# BE-U1000 register map
Vendor: BAIKAL ELECTRONICS, JSC; File version: 1.0
CPU: RISC-V r0p0, little endian, no MPU, no FPU, 3 interrupt priority bits
Registers are 32-bit, read-write, reset 0x0 unless marked. A register's access mark holds for its fields unless they carry their own. Offsets are from the block's base; [hi:lo] are bit positions; {n}, {i} and the like mark numbered series; 'fields as' and 'values as' point back to an identical list; <NAME> marks a mode.

## PWMA0 — Advanced-control Timer
Base 0x14004000
Same registers: PWMA1 0x14005000, PWMA2 0x14006000, PWMA3 0x14007000
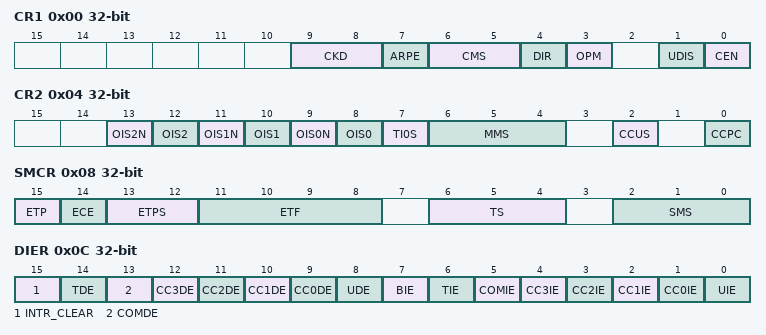
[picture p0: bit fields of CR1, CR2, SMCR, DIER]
0x00 CR1 — Control register 1
  [9:8] CKD — Clock division
    0=DIV1 (Clock is not divided); 1=DIV2 (Clock is divided by 2); 2=DIV4 (Clock is divided by 4)
  [7] ARPE — Auto-reload preload enable
    0=DISABLE; 1=ENABLE
  [6:5] CMS — Center-aligned mode selection
    0=EDGE_ALIGNED (Edge-aligned mode); 1=CENTER_ALIGNED_1 (Center-aligned mode 1); 2=CENTER_ALIGNED_2 (Center-aligned mode 2); 3=CENTER_ALIGNED_3 (Center-aligned mode 3)
  [4] DIR — Direction
    0=UP (Count up); 1=DOWN (Count down)
  [3] OPM — One pulse mode
    0=REPETITIVE (Counter is not stopped at update event); 1=SINGLE (Counter stops counting at the next update event)
  [1] UDIS — Update disable
    0=DISABLE; 1=ENABLE
  [0] CEN — Counter enable
    0=DISABLE; 1=ENABLE
0x04 CR2 — Control register 2
  [13] OIS2N — Output Idle state 2 (OC2N output)
    0=IDLE_LOW (OC2N=1 after a dead-time when MOE=0); 1=IDLE_HIGH (OC2N=1 after a dead-time when MOE=0)
  [12] OIS2 — Output Idle state 2 (OC2 output)
    0=IDLE_LOW (OC2=0 (after a dead-time if OC is implemented) when MOE=0); 1=IDLE_HIGH (OC2=1 (after a dead-time if OC is implemented) when MOE=0)
  [11] OIS1N — Output Idle state 1 (OC1N output)
    0=IDLE_LOW (OC1N=0 after a dead-time when MOE=0); 1=IDLE_HIGH (OC1N=1 after a dead-time when MOE=0)
  [10] OIS1 — Output Idle state 1 (OC1 output)
    0=IDLE_LOW (OC1=0 (after a dead-time if OC is implemented) when MOE=0); 1=IDLE_HIGH (OC1=1 (after a dead-time if OC is implemented) when MOE=0)
  [9] OIS0N — Output Idle state 0 (OC0N output)
    0=IDLE_LOW (OC0N=0 after a dead-time when MOE=0); 1=IDLE_HIGH (OC0N=1 after a dead-time when MOE=0)
  [8] OIS0 — Output Idle state 0 (OC0 output)
    0=IDLE_LOW (OC0=0 (after a dead-time if OC is implemented) when MOE=0); 1=IDLE_HIGH (OC0=1 (after a dead-time if OC is implemented) when MOE=0)
  [7] TI0S — TI0 selection
    0=DISABLE; 1=ENABLE
  [6:4] MMS — Master mode selection
    0=RESET (Reset; TRGO=EGR_UG); 1=ENABLE (Enable; TRGO=CEN or TRGI); 2=UPDATE (Update; TRGO=EUV); 3=CC0IF (Compare Pulse; TRGO=CC0IF); {v}=OC{v-4}REF (Compare; TRGO=OC{v-4}REF) (v=4..7)
  [2] CCUS — Capture/compare control update selection
    0=COMG_ONLY (If buffering of capture/compare control bits \ (CCxE, CCxNE, OCxM) is used; \ Update occurs when CR2_CCPC=1 and COMG=1); 1=COMG_TRGI (If buffering of capture/compare control bits \ (CCxE, CCxNE, OCxM) is used; \ The update occurs when CR2_CCPC=1 and (COMG=1 or posedge(TRGI)))
  [0] CCPC — Capture/Compare preloaded control
    0=DISABLE (CCxE, CCxNE and OCxM bits are not preloaded); 1=ENABLE (CCxE, CCxNE and OCxM bits are preloaded)
0x08 SMCR — Slave mode control register
  [15] ETP — External trigger polarity
    0=NONINVERTED (ETR is non-inverted, active at high level or rising edge); 1=INVERTED (ETR is inverted, active at low level or falling edge)
  [14] ECE — External clock enable
    0=DISABLE; 1=ENABLE
  [13:12] ETPS — External trigger prescaler
    0=DIV1 (ETR signal is not divided); 1=DIV2 (ETR signal is divided by 2); 2=DIV4 (ETR signal is divided by 4); 3=DIV8 (ETR signal is divided by 8)
  [11:8] ETF — External trigger filter
    0=FDIV1 (f_sampling=f_dts; Filter not used); 1=FDIV1_N2 (f_sampling=f_ck_int, N=2); 2=FDIV1_N4 (f_sampling=f_ck_int, N=4); 3=FDIV1_N8 (f_sampling=f_ck_int, N=8); 4=FDIV2_N6 (f_sampling=f_dts/2, N=6); 5=FDIV2_N8 (f_sampling=f_dts/2, N=8); 6=FDIV4_N6 (f_sampling=f_dts/4, N=6); 7=FDIV4_N8 (f_sampling=f_dts/4, N=8); 8=FDIV8_N6 (f_sampling=f_dts/8, N=6); 9=FDIV8_N8 (f_sampling=f_dts/8, N=8); 10=FDIV16_N5 (f_sampling=f_dts/16, N=5); 11=FDIV16_N6 (f_sampling=f_dts/16, N=6); 12=FDIV16_N8 (f_sampling=f_dts/16, N=8); 13=FDIV32_N5 (f_sampling=f_dts/32, N=5); 14=FDIV32_N6 (f_sampling=f_dts/32, N=6); 15=FDIV32_N8 (f_sampling=f_dts/32, N=8)
  [6:4] TS — Trigger selection
    0=ITR0 (Internal Trigger 0 (ITR0)); 1=ITR1 (Internal Trigger 1 (ITR1)); 2=ITR2 (Internal Trigger 2 (ITR2)); 4=TI0F_ED (TI0 Edge Detector (TI0F_ED)); 5=TI0FP0 (Filtered Timer Input 0 (TI0FP0)); 6=TI1FP1 (Filtered Timer Input 1 (TI1FP1)); 7=ETRF (External Trigger Input (ETRF))
  [2:0] SMS — Slave mode selection
    0=DISABLE (Slave mode disabled; At prescaler input: CEN=1 and "internal clock signal"); 4=RESET (Reset mode; posedge(TRGI) resets the counter and updates the registers); 5=GATED (Gated mode; The counter is started by posedge (TRGI); \ The counter is stopped by negedge(TRGI); The counter is not reset.); 6=TRIGGER (Trigger mode; The counter is started by posedge(TRGI); Stopping the counter \ is not controlled. The counter is not reset.); 7=EXTCLK_1 (External Clock Mode 1; The counter is clocked by posedge(TRGI).)
0x0C DIER — DMA/Interrupt enable register
  [all] fields
    0=DISABLE; 1=ENABLE
  [15] INTR_CLEAR — Interrupt clear
  [14] TDE — Trigger DMA request enable
  [13] COMDE — COM DMA request enable
  [n+9] CC{n}DE (n=0..3) — Capture/Compare {n} DMA request enable
  [8] UDE — Update DMA request enable
  [7] BIE — Break interrupt enable
  [6] TIE — Trigger interrupt enable
  [5] COMIE — COM interrupt enable
  [n+1] CC{n}IE (n=0..3) — Capture/Compare {n} interrupt enable
  [0] UIE — Update interrupt enable
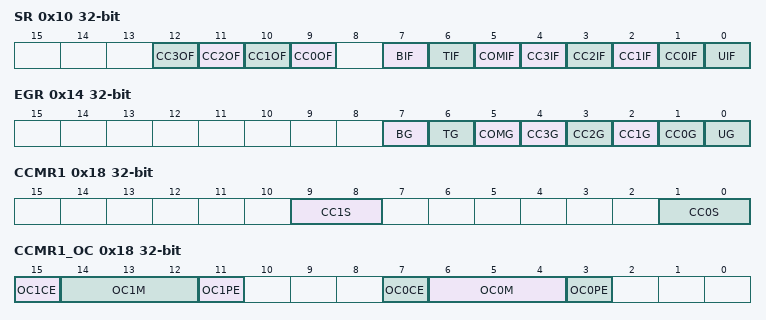
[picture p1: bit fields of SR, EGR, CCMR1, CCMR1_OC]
0x10 SR — Status register
  [all] fields
    0=DISABLE; 1=ENABLE
  [n+9] CC{n}OF (n=0..3) — Capture/Compare {n} overcapture flag
  [7] BIF — Break interrupt flag
  [6] TIF — Trigger interrupt flag
  [5] COMIF — COM interrupt flag
  [n+1] CC{n}IF (n=0..3) — Capture/Compare {n} interrupt flag
  [0] UIF — Update interrupt flag
0x14 EGR — Event generation register
  [all] fields
    0=DISABLE; 1=ENABLE
  [7] BG — Break generation
  [6] TG — Trigger generation
  [5] COMG — Capture/Compare control update generation
  [n+1] CC{n}G (n=0..3) — Capture/Compare {n} generation
  [0] UG — Update generation
0x18 CCMR1 — Capture/Compare mode register 1
  [9:8] CC1S — Capture/Compare 1 selection
    0=OC (Channel 1 configured as output); 1=IC_TI1 (Channel 1 configured as input; IC1 signal connected to TI1); 2=IC_TI0 (Channel 1 configured as input; IC1 signal connected to TI0); 3=IC_TRC (Channel 1 configured as input; IC1 signal connected to TRC when SMCR_TS=1)
  [1:0] CC0S — Capture/Compare 0 selection
    0=OC (Channel 0 configured as output); 1=IC_TI0 (Channel 0 configured as input; IC0 signal connected to TI0); 2=IC_TI1 (Channel 0 configured as input; IC0 signal connected to TI1); 3=IC_TRC (Channel 0 configured as input; IC0 signal connected to TRC when SMCR_TS=1)
0x18 CCMR1_OC — Capture/Compare mode register 1, Output Compare
  [15] OC1CE — Output Compare 1 clear enable
    0=DISABLE; 1=ENABLE
  [14:12] OC1M — Output Compare 1 mode
    0=FROZEN (Frozen; When CNT=CCR1 the output states do not change.); 1=ACTIVE (Set the Channel 1 output to the active level when the comparison circuit \ is triggered; When CNT=CCR1, OC1REF=1 is set.); 2=INACTIVE (Set the Channel 1 output to the inactive level when the comparison circuit \ is triggered; When CNT=CCR1, OC1REF=0 is set.); 3=TOGGLE (Toggle; When CNT=CCR1, OC1REF = not OC1REF is set.); 4=FORCED_INACTIVE (Force switch to the inactive state; OC1REF=0.); 5=FORCED_ACTIVE (Force switch to the active state; OC1REF=1.); 6=PWM1 (PWM mode 1; When counting up, Channel 1 is active (OC1REF=1) \ until (CNT less-than-or-equal CCR1), otherwise Channel 1 is inactive (OC1REF=0); \ When counting down, Channel 1 is inactive (OC1REF=0) \ until (CNT greater-than-or-equal CCR1), otherwise Channel 1 is active (OC1REF=1).); 7=PWM2 (PWM Mode 2; When counting up, Channel 1 is inactive (OC1REF=0) \ until (CNT less-than-or-equal CCR1), otherwise Channel 1 is active (OC1REF=1); \ When counting down, Channel 1 is active (OC1REF=1) \ until (CNT greater-than-or-equal CCR1), otherwise Channel 1 is inactive (OC1REF=1).)
  [11] OC1PE — Output Compare 1 preload enable
    0=DISABLE; 1=ENABLE
  [7] OC0CE — Output Compare 0 clear enable
    0=DISABLE; 1=ENABLE
  [6:4] OC0M — Output Compare 0 mode
    0=FROZEN (Frozen; When CNT=CCR0, the output states do not change.); 1=ACTIVE (Set the Channel 0 output to the active level when the comparison circuit is triggered; When CNT=CCR0, OC0REF=1 is set.); 2=INACTIVE (Set the Channel 0 output to the inactive level when the comparison circuit is triggered; When CNT=CCR0, OC0REF=0 is set.); 3=TOGGLE (Toggle; When CNT=CCR0, OC0REF = not OC0REF is set.); 4=FORCED_INACTIVE (Force switch to the inactive state; OC0REF=0.); 5=FORCED_ACTIVE (Force switch to the active state; OC0REF=1.); 6=PWM1 (PWM mode 1; When counting up, Channel 0 is active (OC0REF=1) \ until (CNT less-than-or-equal CCR0), otherwise Channel 0 is inactive (OC0REF=0); \ When counting down, Channel 0 is inactive (OC0REF=0) \ until (CNT greater-than-or-equal CCR0), otherwise Channel 0 is active (OC0REF=1).); 7=PWM2 (PWM Mode 2; When counting up, Channel 0 is inactive (OC0REF=0) \ until (CNT less-than-or-equal CCR0), otherwise Channel 0 is active (OC0REF=1); \ When counting down, Channel 0 is active (OC0REF=1) \ until (CNT greater-than-or-equal CCR0), otherwise Channel 0 is inactive (OC0REF=1).)
  [3] OC0PE — Output Compare 0 preload enable
    0=DISABLE; 1=ENABLE
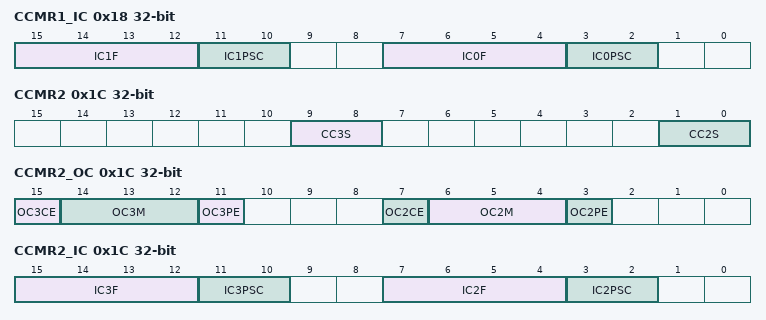
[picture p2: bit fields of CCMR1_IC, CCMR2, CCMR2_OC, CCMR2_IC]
0x18 CCMR1_IC — Capture/Compare mode register 1, Input Capture
  [15:12] IC1F — Input capture 1 filter
    values as SMCR.ETF
  [11:10] IC1PSC — Input capture 1 prescaler
    0=DIV1 (Prescaler is not used); 1=DIV2 (Prescaler is 2); 2=DIV4 (Prescaler is 4); 3=DIV8 (Prescaler is 8)
  [7:4] IC0F — Input capture 0 filter
    values as SMCR.ETF
  [3:2] IC0PSC — Input capture 0 prescaler
    values as IC1PSC
0x1C CCMR2 — Capture/Compare mode register 2
  [9:8] CC3S — Capture/Compare 3 selection
    0=OC (Channel 3 configured as output); 1=IC_TI3 (Channel 3 configured as input; IC3 signal connected to TI3); 2=IC_TI2 (Channel 3 configured as input; IC3 signal connected to TI2); 3=IC (Channel 3 configured as input; IC3 signal connected to TRC when SMCR_TS=1)
  [1:0] CC2S — Capture/Compare 2 selection
    0=OC (Channel 2 configured as output); 1=IC_TI2 (Channel 2 configured as input; IC2 signal connected to TI2); 2=IC_TI3 (Channel 2 configured as input; IC2 signal connected to TI3); 3=IC_TRC (Channel 2 configured as input; IC2 signal connected to TRC when SMCR_TS=1)
0x1C CCMR2_OC — Capture/Compare mode register 2, Output Compare
  [15] OC3CE — Output Compare 3 clear enable
    0=DISABLE; 1=ENABLE
  [14:12] OC3M — Output Compare 3 mode
    0=FROZEN (Frozen; When CNT=CCR3 the output states do not change.); 1=ACTIVE (Set the Channel 3 output to the active level when the comparison circuit \ is triggered; When CNT=CCR3, OC3REF=1 is set.); 2=INACTIVE (Set the Channel 3 output to the inactive level when the comparison circuit \ is triggered; When CNT=CCR3, OC3REF=0 is set.); 3=TOGGLE (Toggle; When CNT=CCR3, OC3REF = not OC3REF is set.); 4=FORCED_INACTIVE (Force switch to the inactive state; OC3REF=0.); 5=FORCED_ACTIVE (Force switch to the active state; OC3REF=1.); 6=PWM1 (PWM mode 1; When counting up, Channel 3 is active (OC3REF=1) \ until (CNT less-than-or-equal CCR3), otherwise Channel 3 is inactive (OC3REF=0); \ When counting down, Channel 3 is inactive (OC3REF=0) \ until (CNT greater-than-or-equal CCR3), otherwise Channel 3 is active (OC3REF=1).); 7=PWM2 (PWM Mode 2; When counting up, Channel 3 is inactive (OC3REF=0) \ until (CNT less-than-or-equal CCR3), otherwise Channel 3 is active (OC3REF=1); \ When counting down, Channel 3 is active (OC3REF=1) \ until (CNT greater-than-or-equal CCR3), otherwise Channel 3 is inactive (OC3REF=1).)
  [11] OC3PE — Output Compare 3 preload enable
    0=DISABLE; 1=ENABLE
  [7] OC2CE — Output Compare 2 clear enable
    0=DISABLE; 1=ENABLE
  [6:4] OC2M — Output Compare 2 mode
    0=FROZEN (Frozen; When CNT=CCR2 the output states do not change.); 1=ACTIVE (Set the Channel 2 output to the active level when the comparison circuit \ is triggered; When CNT=CCR2, OC2REF=1 is set.); 2=INACTIVE (Set the Channel 2 output to the inactive level when the comparison circuit \ is triggered; When CNT=CCR2, OC2REF=0 is set.); 3=TOGGLE (Toggle; When CNT=CCR2, OC2REF = not OC2REF is set.); 4=FORCED_INACTIVE (Force switch to the inactive state; OC2REF=0.); 5=FORCED_ACTIVE (Force switch to the active state; OC2REF=1.); 6=PWM1 (PWM mode 1; When counting up, Channel 2 is active (OC2REF=1) \ until (CNT less-than-or-equal CCR2), otherwise Channel 2 is inactive (OC2REF=0); \ When counting down, Channel 2 is inactive (OC2REF=0) \ until (CNT greater-than-or-equal CCR2), otherwise Channel 2 is active (OC2REF=1).); 7=PWM2 (PWM Mode 2; When counting up, Channel 2 is inactive (OC2REF=0) \ until (CNT less-than-or-equal CCR2), otherwise Channel 2 is active (OC2REF=1); \ When counting down, Channel 2 is active (OC2REF=1) \ until (CNT greater-than-or-equal CCR2), otherwise Channel 2 is inactive (OC2REF=1).)
  [3] OC2PE — Output Compare 2 preload enable
    0=DISABLE; 1=ENABLE
0x1C CCMR2_IC — Capture/Compare mode register 2, Input Capture
  [15:12] IC3F — Input capture 3 filter
    values as SMCR.ETF
  [11:10] IC3PSC — Input capture 3 prescaler
    values as CCMR1_IC.IC1PSC
  [7:4] IC2F — Input capture 2 filter
    values as SMCR.ETF
  [3:2] IC2PSC — Input capture 2 prescaler
    values as CCMR1_IC.IC1PSC
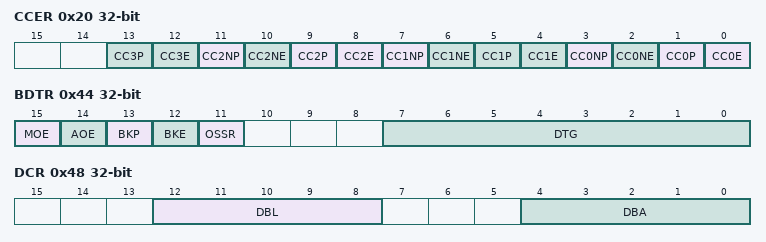
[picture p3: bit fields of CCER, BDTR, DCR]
0x20 CCER — Capture/Compare enable register
  [4n+1] CC{n}P (n=0..3) — Capture/Compare {n} output polarity
    0=HIGH (Channel {n} configured as output: active high); 1=LOW (Channel {n} configured as output: active low); 0=NONINVERTED (Channel {n} configured as input: non-inverted/rising edge); 1=INVERTED (Channel {n} configured as input: inverted/falling edge)
  [4n] CC{n}E (n=0..3) — Capture/Compare {n} output enable
    0=DISABLE (OC{n} is not active); 1=ENABLE (OC{n} signal is output on the corresponding output pin)
  [11] CC2NP — Capture/Compare 2 complementary output polarity
    0=HIGH (Channel 2 configured as output: active high); 1=LOW (Channel 2 configured as output: active low); 0=NONINVERTED (This bit is used in conjunction with CC2P to define the polarity of TI0FP1 and TI1FP1. Refer to CC2P description. Channel 2 configured as input: non-inverted/rising edge); 1=INVERTED (Channel 2 configured as input: inverted/falling edge)
  [10] CC2NE — Capture/Compare 2 complementary output enable
    0=DISABLE (OC2N is not active); 1=ENABLE (OC2N signal is output on the corresponding output pin)
  [7] CC1NP — Capture/Compare 1 complementary output polarity
    0=HIGH (Channel 1 configured as output: active high); 1=LOW (Channel 1 configured as output: active low); 0=NONINVERTED (This bit is used in conjunction with CC1P to define the polarity of TI0FP1 and TI1FP1. Refer to CC1P description. Channel 1 configured as input: non-inverted/rising edge); 1=INVERTED (Channel 1 configured as input: inverted/falling edge)
  [6] CC1NE — Capture/Compare 1 complementary output enable
    0=DISABLE (OC1N is not active); 1=ENABLE (OC1N signal is output on the corresponding output pin)
  [3] CC0NP — Capture/Compare 0 complementary output polarity
    0=HIGH (Channel 0 configured as output: active high); 1=LOW (Channel 0 configured as output: active low); 0=NONINVERTED (This bit is used in conjunction with CC0P to define the polarity of TI0FP1 and TI1FP1. Refer to CC0P description. Channel 0 configured as input: non-inverted/rising edge); 1=INVERTED (Channel 0 configured as input: inverted/falling edge)
  [2] CC0NE — Capture/Compare 0 complementary output enable
    0=DISABLE (OC0N is not active); 1=ENABLE (OC0N signal is output on the corresponding output pin)
0x24 CNT — Counter register
  [15:0] CNT — Counter
0x28 PSC — Prescaler register
  [15:0] PSC — Prescaler
0x2C ARR — Auto-reload register
  [15:0] ARR
0x30 RCR — Repetition counter register
  [7:0] RCR
{0x34+4i} CCR{i} (i=0..3) — Capture/Compare register {i}
  [15:0] CCR{i}
0x44 BDTR — Break and dead-time register
  [15] MOE — Main output enable
    0=DISABLE; 1=ENABLE
  [14] AOE — Automatic output enable
    0=DISABLE (MOE can be set only by software); 1=ENABLE (MOE can be set by software or automatically at the next update event)
  [13] BKP — Break polarity
    0=LOW (Break input BRK is active low); 1=HIGH (Break input BRK is active high)
  [12] BKE — Break enable
    0=DISABLE (Break function disabled); 1=ENABLE (Break function enabled)
  [11] OSSR — Off-state selection for Run mode
    0=DISABLE (When inactive, OCx/OCxN outputs are disabled); 1=ENABLE (When inactive, OC/OCN outputs are enabled with their inactive level as soon as CCxE=1 or CCxNE=1)
  [7:0] DTG — Dead-time generator setup
0x48 DCR — DMA control register
  [12:8] DBL — DMA burst length
    0=1TRANSFER (Transfer is done to 1 register starting from the DMA burst base address); 1=2TRANSFERS (Transfer is done to 2 registers starting from the DMA burst base address); 2=3TRANSFERS (Transfer is done to 3 registers starting from the DMA burst base address); 3=4TRANSFERS (Transfer is done to 4 registers starting from the DMA burst base address); 4=5TRANSFERS (Transfer is done to 5 registers starting from the DMA burst base address*/ PWMA_DCR_DBL_6TRANSFERS (0x5UL << PWMA_DCR_DBL_Pos) /*!< Transfer is done to 6 registers starting from the DMA burst base address); {v}={v+1}TRANSFERS (Transfer is done to {v+1} registers starting from the DMA burst base address) (v=5..17)
  [4:0] DBA — DMA base address
    0=CR1 ((0x00) CR1); 1=CR2 ((0x04) CR2); 2=SMCR ((0x08) SMCR); 3=DIER ((0x0C) DIER); 4=SR ((0x10) SR); 5=EGR ((0x14) EGR); 6=CCMR1 ((0x18) CCMR1); 7=CCMR2 ((0x1C) CCMR2); 8=CCER ((0x20) CCER); 9=CNT ((0x24) CNT); 10=PSC ((0x28) PSC); 11=ARR ((0x2C) ARR); 12=RCR ((0x30) RCR); 13=CCR0 ((0x34) CCR0); 14=CCR1 ((0x38) CCR1); 15=CCR2 ((0x3C) CCR2); 16=CCR3 ((0x40) CCR3); 17=BDTR ((0x44) BDTR); 18=DCR ((0x48) DCR)
0x4C DMAR — DMA address for full transfer register
  [15:0] DBAB — DMA register for burst accesses
